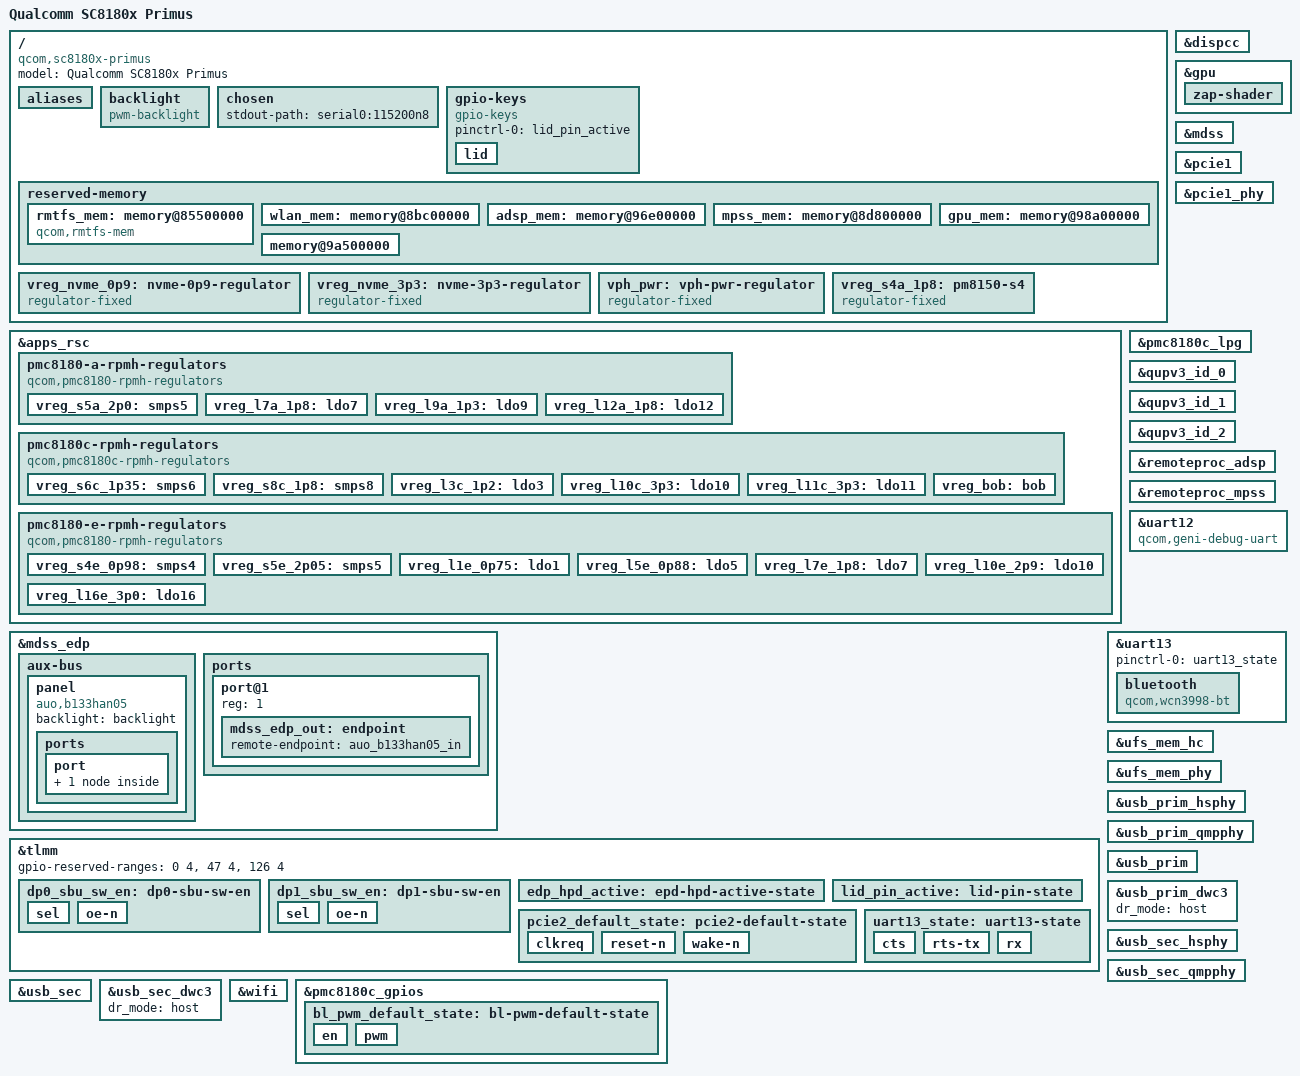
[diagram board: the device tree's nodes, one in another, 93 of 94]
// SPDX-License-Identifier: BSD-3-Clause
/*
 * Copyright (c) 2017-2019, The Linux Foundation. All rights reserved.
 * Copyright (c) 2020-2021, Linaro Limited
 */

/dts-v1/;

#include <dt-bindings/gpio/gpio.h>
#include <dt-bindings/input/gpio-keys.h>
#include <dt-bindings/input/input.h>
#include <dt-bindings/regulator/qcom,rpmh-regulator.h>
#include "sc8180x.dtsi"
#include "pmc8180.dtsi"
#include "pmc8180c.dtsi"

/ {
	model = "Qualcomm SC8180x Primus";
	compatible = "qcom,sc8180x-primus", "qcom,sc8180x";

	aliases {
		serial0 = &uart12;
		serial1 = &uart13;
	};

	backlight: backlight {
		compatible = "pwm-backlight";
		pwms = <&pmc8180c_lpg 4 1000000>;
		enable-gpios = <&pmc8180c_gpios 8 GPIO_ACTIVE_HIGH>;

		pinctrl-names = "default";
		pinctrl-0 = <&bl_pwm_default_state>;
	};

	chosen {
		stdout-path = "serial0:115200n8";
	};

	gpio-keys {
		compatible = "gpio-keys";

		pinctrl-names = "default";
		pinctrl-0 = <&lid_pin_active>;

		lid {
			gpios = <&tlmm 121 GPIO_ACTIVE_HIGH>;
			linux,input-type = <EV_SW>;
			linux,code = <SW_LID>;
			wakeup-source;
			wakeup-event-action = <EV_ACT_DEASSERTED>;
		};
	};

	reserved-memory {
		rmtfs_mem: memory@85500000 {
			compatible = "qcom,rmtfs-mem";
			reg = <0x0 0x85500000 0x0 0x200000>;
			no-map;

			qcom,client-id = <1>;
			qcom,vmid = <15>;
		};

		wlan_mem: memory@8bc00000 {
			reg = <0x0 0x8bc00000 0x0 0x180000>;
			no-map;
		};

		adsp_mem: memory@96e00000 {
			reg = <0x0 0x96e00000 0x0 0x1c00000>;
			no-map;
		};

		mpss_mem: memory@8d800000 {
			reg = <0x0 0x8d800000 0x0 0x9600000>;
			no-map;
		};

		gpu_mem: memory@98a00000 {
			reg = <0x0 0x98a00000 0x0 0x2000>;
			no-map;
		};

		memory@9a500000 {
			reg = <0x0 0x9a500000 0x0 0x600000>;
			no-map;
		};
	};

	vreg_nvme_0p9: nvme-0p9-regulator {
		compatible = "regulator-fixed";
		regulator-name = "vreg_nvme_0p9";

		regulator-min-microvolt = <900000>;
		regulator-max-microvolt = <900000>;

		regulator-always-on;
	};

	vreg_nvme_3p3: nvme-3p3-regulator {
		compatible = "regulator-fixed";
		regulator-name = "vreg_nvme_3p3";

		regulator-min-microvolt = <3300000>;
		regulator-max-microvolt = <3300000>;

		gpio = <&pmc8180c_gpios 11 0>;
		enable-active-high;

		regulator-always-on;
	};

	vph_pwr: vph-pwr-regulator {
		compatible = "regulator-fixed";
		regulator-name = "vph_pwr";
		regulator-min-microvolt = <3700000>;
		regulator-max-microvolt = <3700000>;
	};

	vreg_s4a_1p8: pm8150-s4 {
		compatible = "regulator-fixed";
		regulator-name = "vreg_s4a_1p8";

		regulator-min-microvolt = <1800000>;
		regulator-max-microvolt = <1800000>;

		regulator-always-on;
		regulator-boot-on;

		vin-supply = <&vph_pwr>;
	};
};

&apps_rsc {
	pmc8180-a-rpmh-regulators {
		compatible = "qcom,pmc8180-rpmh-regulators";
		qcom,pmic-id = "a";

		vdd-s5-supply = <&vph_pwr>;
		vdd-l7-l12-l14-l15-supply = <&vreg_s5a_2p0>;

		vreg_s5a_2p0: smps5 {
			regulator-min-microvolt = <2040000>;
			regulator-max-microvolt = <2100000>;
		};

		vreg_l7a_1p8: ldo7 {
			regulator-min-microvolt = <1800000>;
			regulator-max-microvolt = <1800000>;
			regulator-initial-mode = <RPMH_REGULATOR_MODE_HPM>;
		};


		vreg_l9a_1p3: ldo9 {
			regulator-min-microvolt = <1296000>;
			regulator-max-microvolt = <1304000>;
			regulator-initial-mode = <RPMH_REGULATOR_MODE_HPM>;
		};

		vreg_l12a_1p8: ldo12 {
			regulator-min-microvolt = <1800000>;
			regulator-max-microvolt = <1800000>;
			regulator-initial-mode = <RPMH_REGULATOR_MODE_HPM>;
		};
	};

	pmc8180c-rpmh-regulators {
		compatible = "qcom,pmc8180c-rpmh-regulators";
		qcom,pmic-id = "c";

		vdd-s6-supply = <&vph_pwr>;
		vdd-s8-supply = <&vph_pwr>;
		vdd-l2-l3-supply = <&vreg_s6c_1p35>;
		vdd-bob-supply = <&vph_pwr>;

		vreg_s6c_1p35: smps6 {
			regulator-min-microvolt = <1350000>;
			regulator-max-microvolt = <1372000>;
			regulator-initial-mode = <RPMH_REGULATOR_MODE_HPM>;
		};

		vreg_s8c_1p8: smps8 {
			regulator-min-microvolt = <1800000>;
			regulator-max-microvolt = <1800000>;
			regulator-initial-mode = <RPMH_REGULATOR_MODE_HPM>;
			regulator-always-on;
		};

		vreg_l3c_1p2: ldo3 {
			regulator-min-microvolt = <1200000>;
			regulator-max-microvolt = <1200000>;
			regulator-initial-mode = <RPMH_REGULATOR_MODE_HPM>;
		};

		vreg_l10c_3p3: ldo10 {
			regulator-min-microvolt = <3000000>;
			regulator-max-microvolt = <3312000>;
			regulator-initial-mode = <RPMH_REGULATOR_MODE_HPM>;
		};

		vreg_l11c_3p3: ldo11 {
			regulator-min-microvolt = <3296000>;
			regulator-max-microvolt = <3304000>;
			regulator-initial-mode = <RPMH_REGULATOR_MODE_HPM>;
		};

		vreg_bob: bob {
			regulator-min-microvolt = <3296000>;
			regulator-max-microvolt = <3350000>;
			regulator-initial-mode = <RPMH_REGULATOR_MODE_HPM>;
		};
	};

	pmc8180-e-rpmh-regulators {
		compatible = "qcom,pmc8180-rpmh-regulators";
		qcom,pmic-id = "e";

		vdd-s4-supply = <&vph_pwr>;
		vdd-s5-supply = <&vph_pwr>;
		vdd-l2-l10-supply = <&vreg_bob>;
		vdd-l3-l4-l5-l18-supply = <&vreg_s4e_0p98>;
		vdd-l7-l12-l14-l15-supply = <&vreg_s5e_2p05>;
		vdd-l13-l16-l17-supply = <&vreg_bob>;

		vreg_s4e_0p98: smps4 {
			regulator-min-microvolt = <992000>;
			regulator-max-microvolt = <992000>;
			regulator-initial-mode = <RPMH_REGULATOR_MODE_HPM>;
		};

		vreg_s5e_2p05: smps5 {
			regulator-min-microvolt = <2040000>;
			regulator-max-microvolt = <2040000>;
			regulator-initial-mode = <RPMH_REGULATOR_MODE_HPM>;
		};

		vreg_l1e_0p75: ldo1 {
			regulator-min-microvolt = <752000>;
			regulator-max-microvolt = <752000>;
			regulator-initial-mode = <RPMH_REGULATOR_MODE_HPM>;
		};

		vreg_l5e_0p88: ldo5 {
			regulator-min-microvolt = <880000>;
			regulator-max-microvolt = <880000>;
			regulator-initial-mode = <RPMH_REGULATOR_MODE_HPM>;
		};

		vreg_l7e_1p8: ldo7 {
			regulator-min-microvolt = <1800000>;
			regulator-max-microvolt = <1800000>;
			regulator-initial-mode = <RPMH_REGULATOR_MODE_HPM>;
		};

		vreg_l10e_2p9: ldo10 {
			regulator-min-microvolt = <2904000>;
			regulator-max-microvolt = <2904000>;
			regulator-initial-mode = <RPMH_REGULATOR_MODE_HPM>;
		};

		vreg_l16e_3p0: ldo16 {
			regulator-min-microvolt = <3072000>;
			regulator-max-microvolt = <3072000>;
			regulator-initial-mode = <RPMH_REGULATOR_MODE_HPM>;
		};
	};
};

&dispcc {
	status = "okay";
};

&gpu {
	status = "okay";

	zap-shader {
		memory-region = <&gpu_mem>;
		firmware-name = "qcom/sc8180x/qcdxkmsuc8180.mbn";
	};
};

&mdss {
	status = "okay";
};

&mdss_edp {
	status = "okay";

	data-lanes = <0 1 2 3>;

	pinctrl-names = "default";
	pinctrl-0 = <&edp_hpd_active>;

	aux-bus {
		panel {
			//compatible = "edp-panel";
			compatible = "auo,b133han05";
			//no-hpd;

			backlight = <&backlight>;

			ports {
				port {
					auo_b133han05_in: endpoint {
						remote-endpoint = <&mdss_edp_out>;
					};
				};
			};
		};
	};

	ports {
		port@1 {
			reg = <1>;
			mdss_edp_out: endpoint {
				remote-endpoint = <&auo_b133han05_in>;
			};
		};
	};
};

&pcie1 {
	status = "okay";
	perst-gpio = <&tlmm 175 GPIO_ACTIVE_LOW>;
	wake-gpio = <&tlmm 177 GPIO_ACTIVE_HIGH>;
	pinctrl-names = "default";
	pinctrl-0 = <&pcie2_default_state>;
};

&pcie1_phy {
	status = "okay";
	vdda-phy-supply = <&vreg_l5e_0p88>;
	vdda-pll-supply = <&vreg_l3c_1p2>;
};

&pmc8180c_lpg {
	status = "okay";
};

&qupv3_id_0 {
	status = "okay";
};

&qupv3_id_1 {
	status = "okay";
};

&qupv3_id_2 {
	status = "okay";
};

&remoteproc_adsp {
	status = "okay";
	memory-region = <&adsp_mem>;
	firmware-name = "qcom/sc8180x/qcadsp8180.mbn";
};

&remoteproc_mpss {
	status = "okay";
	memory-region = <&mpss_mem>;
	firmware-name = "qcom/sc8180x/qcmpss8180.mbn";
};

&tlmm {
	gpio-reserved-ranges = <0 4>, <47 4>, <126 4>;

	dp0_sbu_sw_en: dp0-sbu-sw-en {
		sel {
			pins = "gpio100";
			function = "gpio";
			output-low;
		};

		oe-n {
			pins = "gpio152";
			function = "gpio";
			output-low;
		};
	};

	dp1_sbu_sw_en: dp1-sbu-sw-en {
		sel {
			pins = "gpio187";
			function = "gpio";
			output-low;
		};

		oe-n {
			pins = "gpio188";
			function = "gpio";
			output-low;
		};
	};

	edp_hpd_active: epd-hpd-active-state {
		pins = "gpio10";
		function = "edp_hot";
	};

	lid_pin_active: lid-pin-state {
		pins = "gpio121";
		function = "gpio";

		input-enable;
		bias-pull-down;
	};

	pcie2_default_state: pcie2-default-state {
		clkreq {
			pins = "gpio176";
			function = "pci_e2";
			bias-pull-up;
		};

		reset-n {
			pins = "gpio175";
			function = "gpio";

			drive-strength = <2>;
			output-low;
			bias-pull-down;
		};

		wake-n {
			pins = "gpio177";
			function = "gpio";

			drive-strength = <2>;
			bias-pull-up;
		};
	};

	uart13_state: uart13-state {
		cts {
			pins = "gpio43";
			function = "qup13";
			bias-pull-down;
		};

		rts-tx {
			pins = "gpio44", "gpio45";
			function = "qup13";
			drive-strength = <2>;
			bias-disable;
		};

		rx {
			pins = "gpio46";
			function = "qup13";
			bias-pull-up;
		};
	};
};

&uart12 {
	compatible = "qcom,geni-debug-uart";
	status = "okay";
};

&uart13 {
	status = "okay";

	pinctrl-names = "default";
	pinctrl-0 = <&uart13_state>;

	bluetooth {
		compatible = "qcom,wcn3998-bt";

		vddio-supply = <&vreg_s4a_1p8>;
		vddxo-supply = <&vreg_l7a_1p8>;
		vddrf-supply = <&vreg_l9a_1p3>;
		vddch0-supply = <&vreg_l11c_3p3>;
		max-speed = <3200000>;
	};
};

&ufs_mem_hc {
	status = "okay";

	reset-gpios = <&tlmm 190 GPIO_ACTIVE_LOW>;

	vcc-supply = <&vreg_l10e_2p9>;
	vcc-max-microamp = <155000>;

	vccq2-supply = <&vreg_l7e_1p8>;
	vccq2-max-microamp = <425000>;
};

&ufs_mem_phy {
	status = "okay";

	vdda-phy-supply = <&vreg_l5e_0p88>;
	vdda-pll-supply = <&vreg_l3c_1p2>;
};

&usb_prim_hsphy {
	status = "okay";
	vdda-pll-supply = <&vreg_l5e_0p88>;
	vdda18-supply = <&vreg_l12a_1p8>;
	vdda33-supply = <&vreg_l16e_3p0>;
};

&usb_prim_qmpphy {
	status = "okay";
	vdda-phy-supply = <&vreg_l3c_1p2>;
	vdda-pll-supply = <&vreg_l5e_0p88>;
};

&usb_prim {
	status = "okay";
};

&usb_prim_dwc3 {
	dr_mode = "host";
};

&usb_sec_hsphy {
	status = "okay";
	vdda-pll-supply = <&vreg_l5e_0p88>;
	vdda18-supply = <&vreg_l12a_1p8>;
	vdda33-supply = <&vreg_l16e_3p0>;
};

&usb_sec_qmpphy {
	status = "okay";
	vdda-phy-supply = <&vreg_l3c_1p2>;
	vdda-pll-supply = <&vreg_l5e_0p88>;
};

&usb_sec {
	status = "okay";
};

&usb_sec_dwc3 {
	dr_mode = "host";
};

&wifi {
	status = "okay";

	memory-region = <&wlan_mem>;

	vdd-0.8-cx-mx-supply = <&vreg_l1e_0p75>;
	vdd-1.8-xo-supply = <&vreg_l7a_1p8>;
	vdd-1.3-rfa-supply = <&vreg_l9a_1p3>;
	vdd-3.3-ch0-supply = <&vreg_l11c_3p3>;
	vdd-3.3-ch1-supply = <&vreg_l10c_3p3>;
};

/* PINCTRL */

&pmc8180c_gpios {
	bl_pwm_default_state: bl-pwm-default-state {
		en {
			pins = "gpio8";
			function = "normal";
		};

		pwm {
			pins = "gpio10";
			function = "func1";
		};
	};
};
